# N32H7xx register map
Vendor: Nationstech Ltd.; File version: 1.0
CPU: CM7 r1p1, little endian, MPU, FPU, 4 interrupt priority bits
Registers are 32-bit, read-write, reset 0x0 unless marked. A register's access mark holds for its fields unless they carry their own. Offsets are from the block's base; [hi:lo] are bit positions; {n}, {i} and the like mark numbered series; 'fields as' and 'values as' point back to an identical list.

## PWR — Power Control
Base 0x58031000
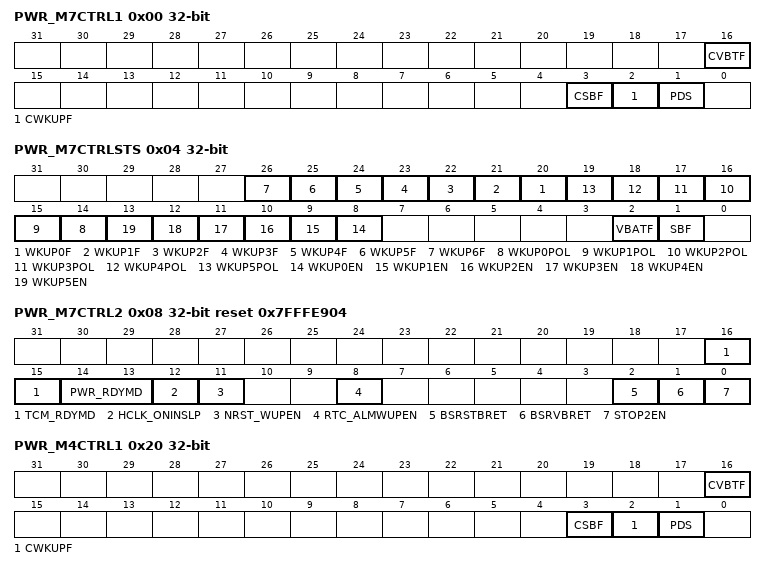
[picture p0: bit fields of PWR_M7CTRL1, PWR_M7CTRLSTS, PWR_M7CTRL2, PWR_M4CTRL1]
0x00 PWR_M7CTRL1 — Power Control Register
  [16] CVBTF, [3] CSBF, [2] CWKUPF, [1] PDS
0x04 PWR_M7CTRLSTS — Power Control/Status Register
  [n+20] WKUP{n}F ro (n=0..6), [n+14] WKUP{n}POL (n=0..5), [n+8] WKUP{n}EN (n=0..5), [2] VBATF ro, [1] SBF ro
0x08 PWR_M7CTRL2 reset 0x7FFFE904 — Power Control Register2
  [16:15] TCM_RDYMD, [14:13] PWR_RDYMD, [12] HCLK_ONINSLP, [11] NRST_WUPEN, [8] RTC_ALMWUPEN, [2] BSRSTBRET, [1] BSRVBRET, [0] STOP2EN
0x20 PWR_M4CTRL1 — Power Control Register
  [16] CVBTF, [3] CSBF, [2] CWKUPF, [1] PDS
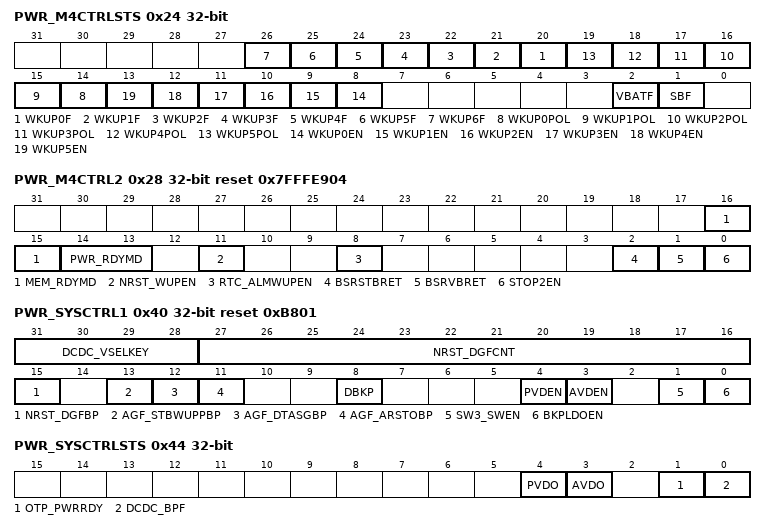
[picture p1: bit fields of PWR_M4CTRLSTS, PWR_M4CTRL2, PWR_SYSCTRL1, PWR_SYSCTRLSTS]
0x24 PWR_M4CTRLSTS — Power Control/Status Register
  fields as PWR_M7CTRLSTS
0x28 PWR_M4CTRL2 reset 0x7FFFE904 — Power Control Register2
  [16:15] MEM_RDYMD, [14:13] PWR_RDYMD, [11] NRST_WUPEN, [8] RTC_ALMWUPEN, [2] BSRSTBRET, [1] BSRVBRET, [0] STOP2EN
0x40 PWR_SYSCTRL1 reset 0xB801 — System Power Control Register
  [31:28] DCDC_VSELKEY, [27:16] NRST_DGFCNT, [15] NRST_DGFBP, [13] AGF_STBWUPPBP, [12] AGF_DTASGBP, [11] AGF_ARSTOBP, [8] DBKP, [4] PVDEN, [3] AVDEN, [1] SW3_SWEN, [0] BKPLDOEN
0x44 PWR_SYSCTRLSTS ro — Power Control/Status Register
  [4] PVDO, [3] AVDO, [1] OTP_PWRRDY, [0] DCDC_BPF
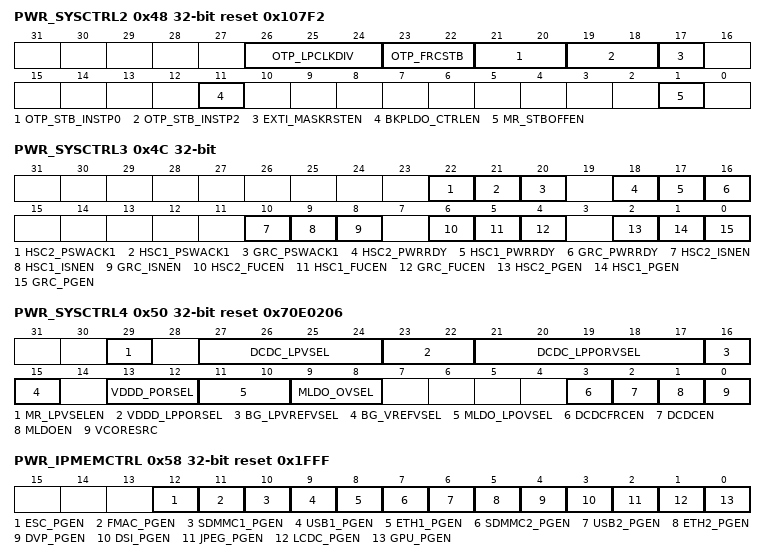
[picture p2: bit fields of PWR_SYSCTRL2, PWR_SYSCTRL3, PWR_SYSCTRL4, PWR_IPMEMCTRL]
0x48 PWR_SYSCTRL2 reset 0x107F2 — Power Control Register 2
  [26:24] OTP_LPCLKDIV, [23:22] OTP_FRCSTB, [21:20] OTP_STB_INSTP0, [19:18] OTP_STB_INSTP2, [17] EXTI_MASKRSTEN, [11] BKPLDO_CTRLEN, [1] MR_STBOFFEN
0x4C PWR_SYSCTRL3 — Power Control Register 3
  [22] HSC2_PSWACK1, [21] HSC1_PSWACK1, [20] GRC_PSWACK1, [18] HSC2_PWRRDY ro, [17] HSC1_PWRRDY ro, [16] GRC_PWRRDY ro, [10] HSC2_ISNEN, [9] HSC1_ISNEN, [8] GRC_ISNEN, [6] HSC2_FUCEN, [5] HSC1_FUCEN, [4] GRC_FUCEN, [2] HSC2_PGEN, [1] HSC1_PGEN, [0] GRC_PGEN
0x50 PWR_SYSCTRL4 reset 0x70E0206 — System Power Control Register 4
  [29] MR_LPVSELEN, [27:24] DCDC_LPVSEL, [23:22] VDDD_LPPORSEL, [21:17] DCDC_LPPORVSEL, [16] BG_LPVREFVSEL, [15] BG_VREFVSEL, [13:12] VDDD_PORSEL, [11:10] MLDO_LPOVSEL, [9:8] MLDO_OVSEL, [3] DCDCFRCEN, [2] DCDCEN, [1] MLDOEN, [0] VCORESRC
0x58 PWR_IPMEMCTRL reset 0x1FFF — IP memory pwer gate control
  [12] ESC_PGEN, [11] FMAC_PGEN, [10] SDMMC1_PGEN, [9] USB1_PGEN, [8] ETH1_PGEN, [7] SDMMC2_PGEN, [6] USB2_PGEN, [5] ETH2_PGEN, [4] DVP_PGEN, [3] DSI_PGEN, [2] JPEG_PGEN, [1] LCDC_PGEN, [0] GPU_PGEN
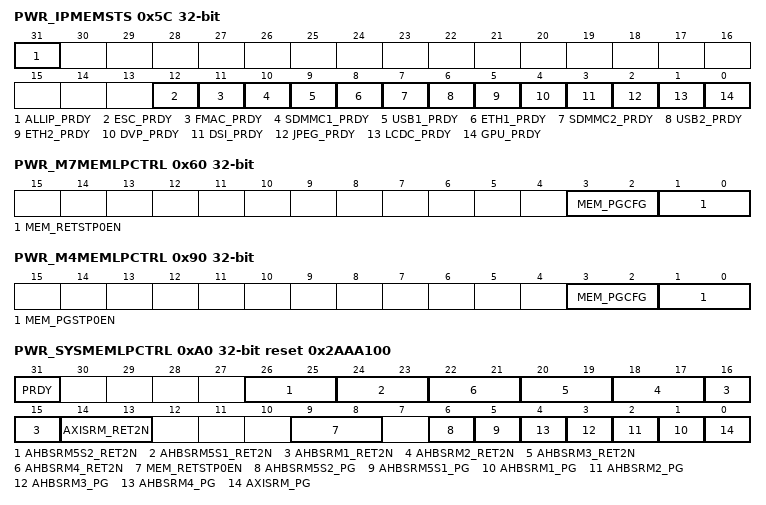
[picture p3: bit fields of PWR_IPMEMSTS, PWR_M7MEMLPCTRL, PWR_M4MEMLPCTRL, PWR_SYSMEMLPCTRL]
0x5C PWR_IPMEMSTS ro — IP memory pwer status register
  [31] ALLIP_PRDY, [12] ESC_PRDY, [11] FMAC_PRDY, [10] SDMMC1_PRDY, [9] USB1_PRDY, [8] ETH1_PRDY, [7] SDMMC2_PRDY, [6] USB2_PRDY, [5] ETH2_PRDY, [4] DVP_PRDY, [3] DSI_PRDY, [2] JPEG_PRDY, [1] LCDC_PRDY, [0] GPU_PRDY
0x60 PWR_M7MEMLPCTRL — CM7 Memory Low power control register
  [3:2] MEM_PGCFG, [1:0] MEM_RETSTP0EN
0x64 PWR_M7MEMLPSTS ro — CM7 Memory low power status register
  [31] TCMRDY
0x68 PWR_M7TCMPG0 — CM7 TCM bank
  [31:0] TCM_PG0
0x6C PWR_M7TCMPG1 — CM7 TCM PG software control register
  [31:0] TCM_PG1
0x70 PWR_M7TCMRET1N0 reset 0xFFFFFFFF — CM7 TCM bank
  [31:0] TCM_RENT1N0
0x74 PWR_M7TCMRET1N1 reset 0xFFFFFFFF — CM7 TCM bank
  [31:0] TCM_RENT1N1
0x78 PWR_M7TCMRET2N0 — CM7 TCM bank
  [31:0] TCM_RENT2N0
0x7C PWR_M7TCMRET2N1 — CM7 TCM bank
  [31:0] TCM_RENT2N1
0x80 PWR_M7TCMRDY0 ro — Inverse of CM7 TCM bank
  [31:0] TCM_RDY
0x84 PWR_M7TCMRDY1 ro — Inverse of CM7 TCM bank
  [31:0] TCM_RDY
0x90 PWR_M4MEMLPCTRL — CM4 Memory low power control register
  [3:2] MEM_PGCFG, [1:0] MEM_PGSTP0EN
0xA0 PWR_SYSMEMLPCTRL reset 0x2AAA100 — Power Control Register 2
  [31] PRDY, [26:25] AHBSRM5S2_RET2N, [24:23] AHBSRM5S1_RET2N, [2n+14:2n+13] AHBSRM{n}_RET2N (n=1..4), [14:13] AXISRM_RET2N, [9:8] MEM_RETSTP0EN, [6] AHBSRM5S2_PG, [5] AHBSRM5S1_PG, [n] AHBSRM{n}_PG (n=1..4), [0] AXISRM_PG
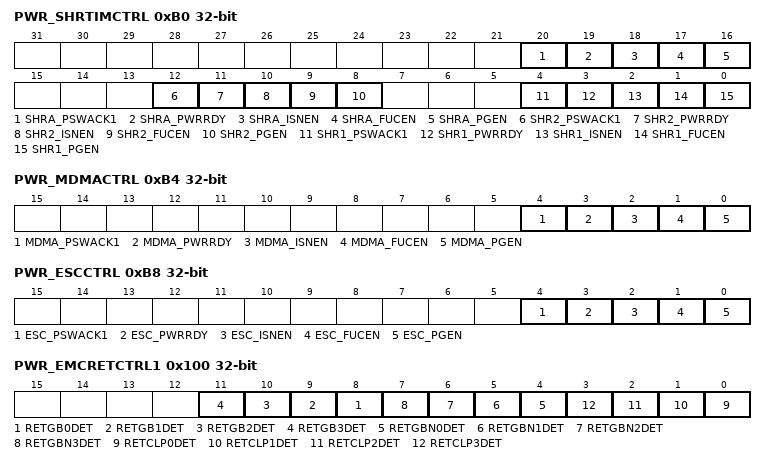
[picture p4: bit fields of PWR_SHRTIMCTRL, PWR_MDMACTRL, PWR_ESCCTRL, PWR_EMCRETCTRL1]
0xB0 PWR_SHRTIMCTRL — SHRTIMER Power Contorl Register
  [20] SHRA_PSWACK1, [19] SHRA_PWRRDY ro, [18] SHRA_ISNEN, [17] SHRA_FUCEN, [16] SHRA_PGEN, [12] SHR2_PSWACK1, [11] SHR2_PWRRDY ro, [10] SHR2_ISNEN, [9] SHR2_FUCEN, [8] SHR2_PGEN, [4] SHR1_PSWACK1, [3] SHR1_PWRRDY ro, [2] SHR1_ISNEN, [1] SHR1_FUCEN, [0] SHR1_PGEN
0xB4 PWR_MDMACTRL — MDMA Power Contorl Register
  [4] MDMA_PSWACK1, [3] MDMA_PWRRDY ro, [2] MDMA_ISNEN, [1] MDMA_FUCEN, [0] MDMA_PGEN
0xB8 PWR_ESCCTRL — ETHCAT Power Contorl Register
  [4] ESC_PSWACK1, [3] ESC_PWRRDY ro, [2] ESC_ISNEN, [1] ESC_FUCEN, [0] ESC_PGEN
0x100 PWR_EMCRETCTRL1 — EMC CONTROL REGISTER for EMC sets
  [n+8] RETGB{n}DET (n=0..3), [n+4] RETGBN{n}DET (n=0..3), [n] RETCLP{n}DET (n=0..3)
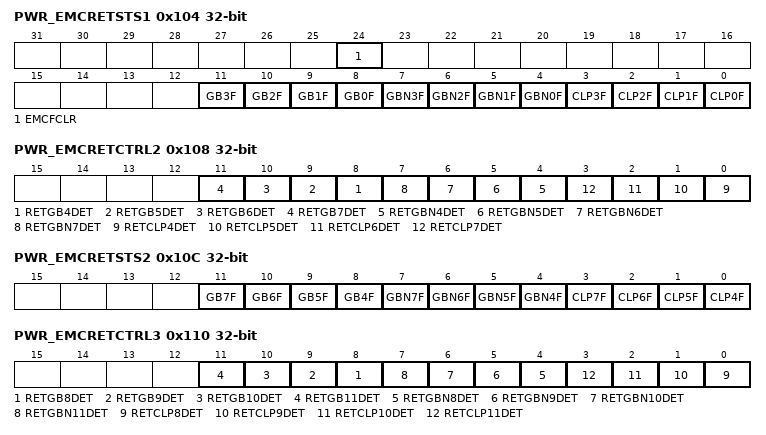
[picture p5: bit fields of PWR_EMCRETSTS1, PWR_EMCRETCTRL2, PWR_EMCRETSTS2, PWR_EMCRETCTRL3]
0x104 PWR_EMCRETSTS1 — EMC Flag REGISTER for EMC sets
  [24] EMCFCLR, [n+8] GB{n}F ro (n=0..3), [n+4] GBN{n}F ro (n=0..3), [n] CLP{n}F ro (n=0..3)
0x108 PWR_EMCRETCTRL2 — EMC CONTROL REGISTER for EMC sets
  [n+4] RETGB{n}DET (n=4..7), [n] RETGBN{n}DET (n=4..7), [n-4] RETCLP{n}DET (n=4..7)
0x10C PWR_EMCRETSTS2 ro — EMC Flag REGISTER for EMC sets
  [n+4] GB{n}F (n=4..7), [n] GBN{n}F (n=4..7), [n-4] CLP{n}F (n=4..7)
0x110 PWR_EMCRETCTRL3 — EMC CONTROL REGISTER for EMC sets
  [n] RETGB{n}DET (n=8..11), [n-4] RETGBN{n}DET (n=8..11), [n-8] RETCLP{n}DET (n=8..11)
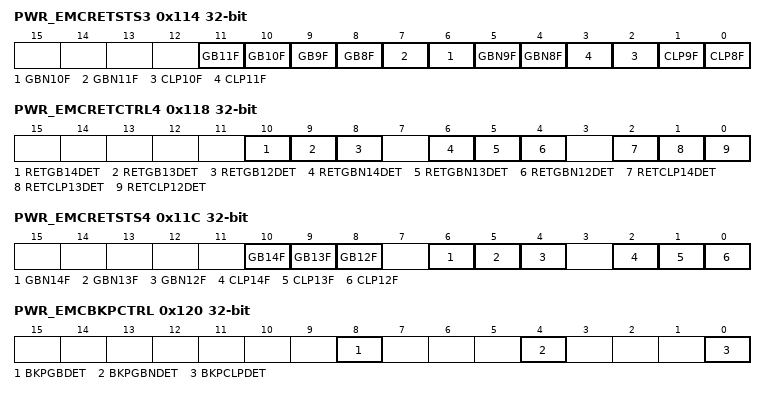
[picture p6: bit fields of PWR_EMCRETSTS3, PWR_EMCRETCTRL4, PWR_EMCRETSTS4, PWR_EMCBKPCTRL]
0x114 PWR_EMCRETSTS3 ro — EMC Flag REGISTER for EMC sets
  [n] GB{n}F (n=8..11), [n-4] GBN{n}F (n=8..11), [n-8] CLP{n}F (n=8..11)
0x118 PWR_EMCRETCTRL4 — EMC CONTROL REGISTER for EMC sets
  [10] RETGB14DET, [9] RETGB13DET, [8] RETGB12DET, [6] RETGBN14DET, [5] RETGBN13DET, [4] RETGBN12DET, [2] RETCLP14DET, [1] RETCLP13DET, [0] RETCLP12DET
0x11C PWR_EMCRETSTS4 ro — EMC Flag REGISTER for EMC sets
  [10] GB14F, [9] GB13F, [8] GB12F, [6] GBN14F, [5] GBN13F, [4] GBN12F, [2] CLP14F, [1] CLP13F, [0] CLP12F
0x120 PWR_EMCBKPCTRL — EMC CONTROL REGISTER for EMC set in BKP domain
  [8] BKPGBDET, [4] BKPGBNDET, [0] BKPCLPDET
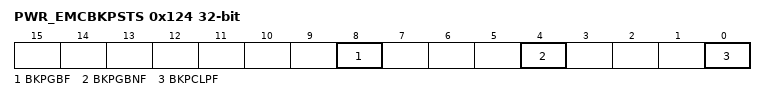
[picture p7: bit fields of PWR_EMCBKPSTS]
0x124 PWR_EMCBKPSTS ro — EMC flag for EMC set in BKP domain
  [8] BKPGBF, [4] BKPGBNF, [0] BKPCLPF
